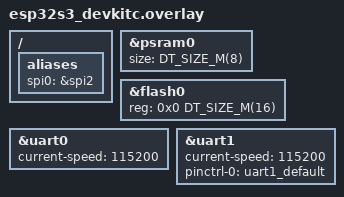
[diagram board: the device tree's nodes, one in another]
/ {
    aliases {
        spi0 = &spi2;     /* Zephyr will refer to SPI2 as spi0 */
    };
};

/* 8MB PSRAM */
&psram0 {
	size = <DT_SIZE_M(8)>;
};

/* 16MB FLASH */
&flash0 {
	/delete-node/ partitions;
};

&flash0 {
	reg = <0x0 DT_SIZE_M(16)>;
};

/* UART 0 (console) */
&uart0 {
    current-speed = <115200>;
    status = "okay";
};

/* UART 1 - raspberry pi bidirectional link */
&uart1 {
	status = "okay";
	current-speed = <115200>;
	pinctrl-0 = <&uart1_default>;
	pinctrl-names = "default";
};

#include <espressif/partitions_0x0_amp_16M.dtsi>
/* --------- */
